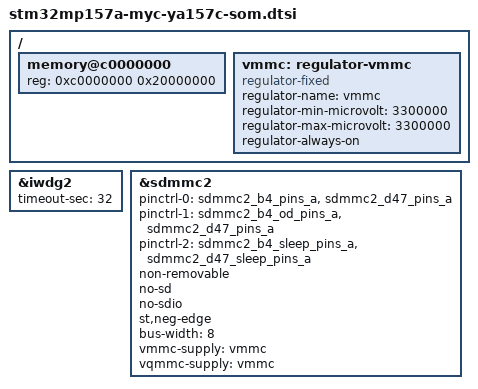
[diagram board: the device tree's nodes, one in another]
// SPDX-License-Identifier: (GPL-2.0-or-later OR BSD-3-Clause)
/*
 * MYIR MYC-YA157C core board: STM32MP157AAC (650 MHz, no CRYP, TFBGA361
 * "AC" package), 512 MB DDR3, 4 GB eMMC on SDMMC2. No PMIC: the core rails
 * come from fixed DC-DC converters.
 *
 * Booted by TF-A BL2 with SP_MIN as BL32, which also serves SCMI.
 */

#include "stm32mp157.dtsi"
#include "stm32mp15xa.dtsi"
#include "stm32mp15-pinctrl.dtsi"
#include "stm32mp15xxac-pinctrl.dtsi"
#include "stm32mp15-sp-min-scmi.dtsi"

/ {
	memory@c0000000 {
		device_type = "memory";
		reg = <0xc0000000 0x20000000>;
	};

	vmmc: regulator-vmmc {
		compatible = "regulator-fixed";
		regulator-name = "vmmc";
		regulator-min-microvolt = <3300000>;
		regulator-max-microvolt = <3300000>;
		regulator-always-on;
	};
};

&iwdg2 {
	timeout-sec = <32>;
	status = "okay";
};

/* eMMC */
&sdmmc2 {
	pinctrl-names = "default", "opendrain", "sleep";
	pinctrl-0 = <&sdmmc2_b4_pins_a &sdmmc2_d47_pins_a>;
	pinctrl-1 = <&sdmmc2_b4_od_pins_a &sdmmc2_d47_pins_a>;
	pinctrl-2 = <&sdmmc2_b4_sleep_pins_a &sdmmc2_d47_sleep_pins_a>;
	non-removable;
	no-sd;
	no-sdio;
	st,neg-edge;
	bus-width = <8>;
	vmmc-supply = <&vmmc>;
	vqmmc-supply = <&vmmc>;
	status = "okay";
};
